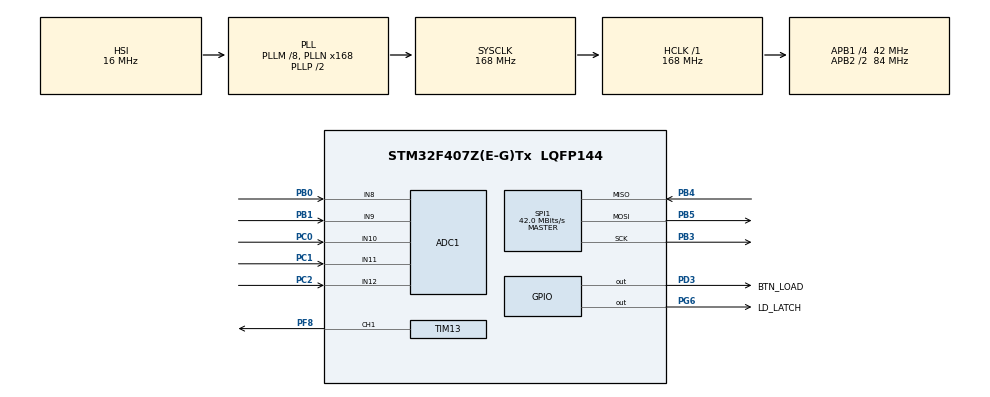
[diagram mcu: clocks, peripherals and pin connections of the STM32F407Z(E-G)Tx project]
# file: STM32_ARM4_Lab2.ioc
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ADC1.Channel-0\#ChannelRegularConversion=ADC_CHANNEL_8
ADC1.Channel-1\#ChannelRegularConversion=ADC_CHANNEL_9
ADC1.Channel-2\#ChannelRegularConversion=ADC_CHANNEL_10
ADC1.Channel-3\#ChannelRegularConversion=ADC_CHANNEL_11
ADC1.Channel-4\#ChannelRegularConversion=ADC_CHANNEL_12
ADC1.NbrOfConversion=5
ADC1.NbrOfConversionFlag=1
ADC1.Rank-0\#ChannelRegularConversion=1
ADC1.Rank-1\#ChannelRegularConversion=2
ADC1.Rank-2\#ChannelRegularConversion=3
ADC1.Rank-3\#ChannelRegularConversion=4
ADC1.Rank-4\#ChannelRegularConversion=5
ADC1.SamplingTime-0\#ChannelRegularConversion=ADC_SAMPLETIME_3CYCLES
ADC1.SamplingTime-1\#ChannelRegularConversion=ADC_SAMPLETIME_3CYCLES
ADC1.SamplingTime-2\#ChannelRegularConversion=ADC_SAMPLETIME_3CYCLES
ADC1.SamplingTime-3\#ChannelRegularConversion=ADC_SAMPLETIME_3CYCLES
ADC1.SamplingTime-4\#ChannelRegularConversion=ADC_SAMPLETIME_3CYCLES
ADC1.ScanConvMode=ENABLE
ADC1.master=1
Dma.ADC1.0.Direction=DMA_PERIPH_TO_MEMORY
Dma.ADC1.0.FIFOMode=DMA_FIFOMODE_DISABLE
Dma.ADC1.0.Instance=DMA2_Stream0
Dma.ADC1.0.MemDataAlignment=DMA_MDATAALIGN_HALFWORD
Dma.ADC1.0.MemInc=DMA_MINC_ENABLE
Dma.ADC1.0.Mode=DMA_CIRCULAR
Dma.ADC1.0.PeriphDataAlignment=DMA_PDATAALIGN_HALFWORD
Dma.ADC1.0.PeriphInc=DMA_PINC_DISABLE
Dma.ADC1.0.Priority=DMA_PRIORITY_LOW
Dma.Request0=ADC1
Mcu.Family=STM32F4
Mcu.Name=STM32F407Z(E-G)Tx
Mcu.Package=LQFP144
NVIC.DMA2_Stream0_IRQn=true\:0\:0\:false\:false\:true\:false\:true
NVIC.PriorityGroup=NVIC_PRIORITYGROUP_4
NVIC.TIM2_IRQn=true\:0\:0\:false\:false\:true\:true\:true
PA13.Mode=Serial_Wire
PA13.Signal=SYS_JTMS-SWDIO
PA14.Mode=Serial_Wire
PA14.Signal=SYS_JTCK-SWCLK
PB0.Signal=ADCx_IN8
PB1.Signal=ADCx_IN9
PB3.Mode=Full_Duplex_Master
PB3.Signal=SPI1_SCK
PB4.Mode=Full_Duplex_Master
PB4.Signal=SPI1_MISO
PB5.Mode=Full_Duplex_Master
PB5.Signal=SPI1_MOSI
PC0.Signal=ADCx_IN10
PC1.Signal=ADCx_IN11
PC2.Signal=ADCx_IN12
PD3.GPIO_Label=BTN_LOAD
PD3.Signal=GPIO_Output
PF8.Signal=S_TIM13_CH1
PG6.GPIO_Label=LD_LATCH
PG6.Signal=GPIO_Output
PH0-OSC_IN.Mode=HSE-External-Oscillator
PH0-OSC_IN.Signal=RCC_OSC_IN
PH1-OSC_OUT.Mode=HSE-External-Oscillator
PH1-OSC_OUT.Signal=RCC_OSC_OUT
ProjectManager.HeapSize=0x200
ProjectManager.StackSize=0x400
ProjectManager.TargetToolchain=STM32CubeIDE
RCC.48MHZClocksFreq_Value=84000000
RCC.AHBFreq_Value=168000000
RCC.APB1CLKDivider=RCC_HCLK_DIV4
RCC.APB1Freq_Value=42000000
RCC.APB1TimFreq_Value=84000000
RCC.APB2CLKDivider=RCC_HCLK_DIV2
RCC.APB2Freq_Value=84000000
RCC.APB2TimFreq_Value=168000000
RCC.CortexFreq_Value=168000000
RCC.HCLKFreq_Value=168000000
RCC.HSE_VALUE=8000000
RCC.HSI_VALUE=16000000
RCC.LSE_VALUE=32768
RCC.PLLM=8
RCC.PLLN=168
RCC.SYSCLKFreq_VALUE=168000000
RCC.SYSCLKSource=RCC_SYSCLKSOURCE_PLLCLK
RCC.VCOOutputFreq_Value=336000000
SH.ADCx_IN10.0=ADC1_IN10,IN10
SH.ADCx_IN11.0=ADC1_IN11,IN11
SH.ADCx_IN12.0=ADC1_IN12,IN12
SH.ADCx_IN8.0=ADC1_IN8,IN8
SH.ADCx_IN9.0=ADC1_IN9,IN9
SH.S_TIM13_CH1.0=TIM13_CH1,PWM Generation1 CH1
SPI1.CalculateBaudRate=42.0 MBits/s
SPI1.Direction=SPI_DIRECTION_2LINES
SPI1.Mode=SPI_MODE_MASTER
SPI1.VirtualType=VM_MASTER
TIM13.Channel=TIM_CHANNEL_1
TIM13.Period=99
TIM13.Prescaler=840-1
TIM2.Period=99
TIM2.Prescaler=840-1
VP_TIM13_VS_ClockSourceINT.Mode=Enable_Timer
VP_TIM2_VS_ClockSourceINT.Mode=Internal
board=custom

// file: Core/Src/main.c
/* USER CODE BEGIN Header */
/**
  ******************************************************************************
  * @file           : main.c
  * @brief          : Main program body
  ******************************************************************************
  * @attention
  *
  * <h2><center>&copy; Copyright (c) 2024 STMicroelectronics.
  * All rights reserved.</center></h2>
  *
  * This software component is licensed by ST under BSD 3-Clause license,
  * the "License"; You may not use this file except in compliance with the
  * License. You may obtain a copy of the License at:
  *                        opensource.org/licenses/BSD-3-Clause
  *
  ******************************************************************************
  */
/* USER CODE END Header */
#include "main.h"

ADC_HandleTypeDef hadc1;
DMA_HandleTypeDef hdma_adc1;

SPI_HandleTypeDef hspi1;

TIM_HandleTypeDef htim2;
TIM_HandleTypeDef htim13;

void SystemClock_Config(void);
static void MX_GPIO_Init(void);
static void MX_DMA_Init(void);
static void MX_ADC1_Init(void);
static void MX_TIM13_Init(void);
static void MX_TIM2_Init(void);
static void MX_SPI1_Init(void);

int main(void)
{

  /* MCU Configuration--------------------------------------------------------*/

  /* Reset of all peripherals, Initializes the Flash interface and the Systick. */
  HAL_Init();

  /* Configure the system clock */
  SystemClock_Config();

  /* Initialize all configured peripherals */
  MX_GPIO_Init();
  MX_DMA_Init();
  MX_ADC1_Init();
  MX_TIM13_Init();
  MX_TIM2_Init();
  MX_SPI1_Init();
  /* USER CODE BEGIN 2 */
  HAL_TIM_Base_Start_IT(&htim2);
  HAL_TIM_Base_Start_IT(&htim13);
  /* USER CODE END 2 */

  /* Infinite loop */
  while (1)
  {

  }
}

void SystemClock_Config(void)
{
  RCC_OscInitTypeDef RCC_OscInitStruct = {0};
  RCC_ClkInitTypeDef RCC_ClkInitStruct = {0};

  /** Configure the main internal regulator output voltage
  */
  __HAL_RCC_PWR_CLK_ENABLE();
  __HAL_PWR_VOLTAGESCALING_CONFIG(PWR_REGULATOR_VOLTAGE_SCALE1);
  /** Initializes the RCC Oscillators according to the specified parameters
  * in the RCC_OscInitTypeDef structure.
  */
  RCC_OscInitStruct.OscillatorType = RCC_OSCILLATORTYPE_HSI;
  RCC_OscInitStruct.HSIState = RCC_HSI_ON;
  RCC_OscInitStruct.HSICalibrationValue = RCC_HSICALIBRATION_DEFAULT;
  RCC_OscInitStruct.PLL.PLLState = RCC_PLL_ON;
  RCC_OscInitStruct.PLL.PLLSource = RCC_PLLSOURCE_HSI;
  RCC_OscInitStruct.PLL.PLLM = 8;
  RCC_OscInitStruct.PLL.PLLN = 168;
  RCC_OscInitStruct.PLL.PLLP = RCC_PLLP_DIV2;
  RCC_OscInitStruct.PLL.PLLQ = 4;
  if (HAL_RCC_OscConfig(&RCC_OscInitStruct) != HAL_OK)
  {
    Error_Handler();
  }
  /** Initializes the CPU, AHB and APB buses clocks
  */
  RCC_ClkInitStruct.ClockType = RCC_CLOCKTYPE_HCLK|RCC_CLOCKTYPE_SYSCLK
                              |RCC_CLOCKTYPE_PCLK1|RCC_CLOCKTYPE_PCLK2;
  RCC_ClkInitStruct.SYSCLKSource = RCC_SYSCLKSOURCE_PLLCLK;
  RCC_ClkInitStruct.AHBCLKDivider = RCC_SYSCLK_DIV1;
  RCC_ClkInitStruct.APB1CLKDivider = RCC_HCLK_DIV4;
  RCC_ClkInitStruct.APB2CLKDivider = RCC_HCLK_DIV2;

  if (HAL_RCC_ClockConfig(&RCC_ClkInitStruct, FLASH_LATENCY_5) != HAL_OK)
  {
    Error_Handler();
  }
}

static void MX_ADC1_Init(void)
{

  ADC_ChannelConfTypeDef sConfig = {0};

  /** Configure the global features of the ADC (Clock, Resolution, Data Alignment and number of conversion)
  */
  hadc1.Instance = ADC1;
  hadc1.Init.ClockPrescaler = ADC_CLOCK_SYNC_PCLK_DIV4;
  hadc1.Init.Resolution = ADC_RESOLUTION_12B;
  hadc1.Init.ScanConvMode = ENABLE;
  hadc1.Init.ContinuousConvMode = DISABLE;
  hadc1.Init.DiscontinuousConvMode = DISABLE;
  hadc1.Init.ExternalTrigConvEdge = ADC_EXTERNALTRIGCONVEDGE_NONE;
  hadc1.Init.ExternalTrigConv = ADC_SOFTWARE_START;
  hadc1.Init.DataAlign = ADC_DATAALIGN_RIGHT;
  hadc1.Init.NbrOfConversion = 5;
  hadc1.Init.DMAContinuousRequests = DISABLE;
  hadc1.Init.EOCSelection = ADC_EOC_SINGLE_CONV;
  if (HAL_ADC_Init(&hadc1) != HAL_OK)
  {
    Error_Handler();
  }
  /** Configure for the selected ADC regular channel its corresponding rank in the sequencer and its sample time.
  */
  sConfig.Channel = ADC_CHANNEL_8;
  sConfig.Rank = 1;
  sConfig.SamplingTime = ADC_SAMPLETIME_3CYCLES;
  if (HAL_ADC_ConfigChannel(&hadc1, &sConfig) != HAL_OK)
  {
    Error_Handler();
  }
  /** Configure for the selected ADC regular channel its corresponding rank in the sequencer and its sample time.
  */
  sConfig.Channel = ADC_CHANNEL_9;
  sConfig.Rank = 2;
  if (HAL_ADC_ConfigChannel(&hadc1, &sConfig) != HAL_OK)
  {
    Error_Handler();
  }
  /** Configure for the selected ADC regular channel its corresponding rank in the sequencer and its sample time.
  */
  sConfig.Channel = ADC_CHANNEL_10;
  sConfig.Rank = 3;
  if (HAL_ADC_ConfigChannel(&hadc1, &sConfig) != HAL_OK)
  {
    Error_Handler();
  }
  /** Configure for the selected ADC regular channel its corresponding rank in the sequencer and its sample time.
  */
  sConfig.Channel = ADC_CHANNEL_11;
  sConfig.Rank = 4;
  if (HAL_ADC_ConfigChannel(&hadc1, &sConfig) != HAL_OK)
  {
    Error_Handler();
  }
  /** Configure for the selected ADC regular channel its corresponding rank in the sequencer and its sample time.
  */
  sConfig.Channel = ADC_CHANNEL_12;
  sConfig.Rank = 5;
  if (HAL_ADC_ConfigChannel(&hadc1, &sConfig) != HAL_OK)
  {
    Error_Handler();
  }

}

static void MX_SPI1_Init(void)
{

  /* SPI1 parameter configuration*/
  hspi1.Instance = SPI1;
  hspi1.Init.Mode = SPI_MODE_MASTER;
  hspi1.Init.Direction = SPI_DIRECTION_2LINES;
  hspi1.Init.DataSize = SPI_DATASIZE_8BIT;
  hspi1.Init.CLKPolarity = SPI_POLARITY_LOW;
  hspi1.Init.CLKPhase = SPI_PHASE_1EDGE;
  hspi1.Init.NSS = SPI_NSS_SOFT;
  hspi1.Init.BaudRatePrescaler = SPI_BAUDRATEPRESCALER_2;
  hspi1.Init.FirstBit = SPI_FIRSTBIT_MSB;
  hspi1.Init.TIMode = SPI_TIMODE_DISABLE;
  hspi1.Init.CRCCalculation = SPI_CRCCALCULATION_DISABLE;
  hspi1.Init.CRCPolynomial = 10;
  if (HAL_SPI_Init(&hspi1) != HAL_OK)
  {
    Error_Handler();
  }

}

static void MX_TIM2_Init(void)
{

  TIM_ClockConfigTypeDef sClockSourceConfig = {0};
  TIM_MasterConfigTypeDef sMasterConfig = {0};

  htim2.Instance = TIM2;
  htim2.Init.Prescaler = 840-1;
  htim2.Init.CounterMode = TIM_COUNTERMODE_UP;
  htim2.Init.Period = 99;
  htim2.Init.ClockDivision = TIM_CLOCKDIVISION_DIV1;
  htim2.Init.AutoReloadPreload = TIM_AUTORELOAD_PRELOAD_DISABLE;
  if (HAL_TIM_Base_Init(&htim2) != HAL_OK)
  {
    Error_Handler();
  }
  sClockSourceConfig.ClockSource = TIM_CLOCKSOURCE_INTERNAL;
  if (HAL_TIM_ConfigClockSource(&htim2, &sClockSourceConfig) != HAL_OK)
  {
    Error_Handler();
  }
  sMasterConfig.MasterOutputTrigger = TIM_TRGO_RESET;
  sMasterConfig.MasterSlaveMode = TIM_MASTERSLAVEMODE_DISABLE;
  if (HAL_TIMEx_MasterConfigSynchronization(&htim2, &sMasterConfig) != HAL_OK)
  {
    Error_Handler();
  }

}

static void MX_TIM13_Init(void)
{

  TIM_OC_InitTypeDef sConfigOC = {0};

  htim13.Instance = TIM13;
  htim13.Init.Prescaler = 840-1;
  htim13.Init.CounterMode = TIM_COUNTERMODE_UP;
  htim13.Init.Period = 99;
  htim13.Init.ClockDivision = TIM_CLOCKDIVISION_DIV1;
  htim13.Init.AutoReloadPreload = TIM_AUTORELOAD_PRELOAD_DISABLE;
  if (HAL_TIM_Base_Init(&htim13) != HAL_OK)
  {
    Error_Handler();
  }
  if (HAL_TIM_PWM_Init(&htim13) != HAL_OK)
  {
    Error_Handler();
  }
  sConfigOC.OCMode = TIM_OCMODE_PWM1;
  sConfigOC.Pulse = 0;
  sConfigOC.OCPolarity = TIM_OCPOLARITY_HIGH;
  sConfigOC.OCFastMode = TIM_OCFAST_DISABLE;
  if (HAL_TIM_PWM_ConfigChannel(&htim13, &sConfigOC, TIM_CHANNEL_1) != HAL_OK)
  {
    Error_Handler();
  }
  HAL_TIM_MspPostInit(&htim13);

}

static void MX_DMA_Init(void)
{

  /* DMA controller clock enable */
  __HAL_RCC_DMA2_CLK_ENABLE();

  /* DMA interrupt init */
  /* DMA2_Stream0_IRQn interrupt configuration */
  HAL_NVIC_SetPriority(DMA2_Stream0_IRQn, 0, 0);
  HAL_NVIC_EnableIRQ(DMA2_Stream0_IRQn);

}

static void MX_GPIO_Init(void)
{
  GPIO_InitTypeDef GPIO_InitStruct = {0};

  /* GPIO Ports Clock Enable */
  __HAL_RCC_GPIOF_CLK_ENABLE();
  __HAL_RCC_GPIOH_CLK_ENABLE();
  __HAL_RCC_GPIOC_CLK_ENABLE();
  __HAL_RCC_GPIOB_CLK_ENABLE();
  __HAL_RCC_GPIOG_CLK_ENABLE();
  __HAL_RCC_GPIOA_CLK_ENABLE();
  __HAL_RCC_GPIOD_CLK_ENABLE();

  /*Configure GPIO pin Output Level */
  HAL_GPIO_WritePin(LD_LATCH_GPIO_Port, LD_LATCH_Pin, GPIO_PIN_RESET);

  /*Configure GPIO pin Output Level */
  HAL_GPIO_WritePin(BTN_LOAD_GPIO_Port, BTN_LOAD_Pin, GPIO_PIN_RESET);

  /*Configure GPIO pin : LD_LATCH_Pin */
  GPIO_InitStruct.Pin = LD_LATCH_Pin;
  GPIO_InitStruct.Mode = GPIO_MODE_OUTPUT_PP;
  GPIO_InitStruct.Pull = GPIO_NOPULL;
  GPIO_InitStruct.Speed = GPIO_SPEED_FREQ_LOW;
  HAL_GPIO_Init(LD_LATCH_GPIO_Port, &GPIO_InitStruct);

  /*Configure GPIO pin : BTN_LOAD_Pin */
  GPIO_InitStruct.Pin = BTN_LOAD_Pin;
  GPIO_InitStruct.Mode = GPIO_MODE_OUTPUT_PP;
  GPIO_InitStruct.Pull = GPIO_NOPULL;
  GPIO_InitStruct.Speed = GPIO_SPEED_FREQ_LOW;
  HAL_GPIO_Init(BTN_LOAD_GPIO_Port, &GPIO_InitStruct);

}

void Error_Handler(void)
{
  __disable_irq();
  while (1)
  {
  }
}

/************************ (C) COPYRIGHT STMicroelectronics *****END OF FILE****/
